# telemetry_receiver_wrap: IP-XACT component
VLNV tenstorrent.com:ocah:telemetry_receiver_wrap:1.0

## Address spaces and blocks
telemetry_receiver_wrap_mmap.telemetry_receiver_wrap: base 'h0, range 'h300, width 32

## Registers
Registers are 32-bit, read-only, reset 0x0 unless marked. A register's access mark holds for its fields unless they carry their own. Offsets are from the block's base; lines under a group give offsets from that group; [hi:lo] are bit positions; {n}, {i} and the like mark numbered series; 'fields as' and 'values as' point back to an identical list; <NAME> marks a mode.

## telemetry_receiver_wrap_mmap.telemetry_receiver_wrap — Wrapper address map instantiating the telemetry receiver channels.
Base 0x00000000
{0x0+0x100*i} telemetry_receiver[{i}] (i=0..2) group — Configuration, status, and data-buffer registers for a single telemetry receiver channel.
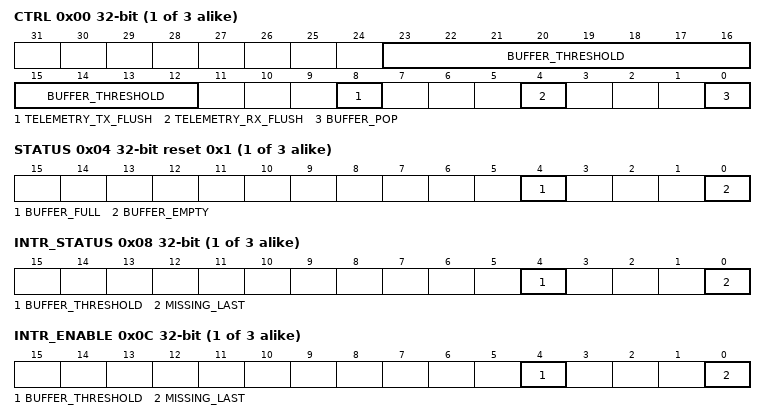
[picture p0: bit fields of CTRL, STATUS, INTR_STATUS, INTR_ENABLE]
  0x00 CTRL access per field — Control Register
    [23:12] BUFFER_THRESHOLD rw — Telemetry Message Buffer Threshold. The Telemetry Buffer Threshold Interrupt is asserted when the number of entries in the buffer is greater than this value. Only the low log2(queue depth)+1 bits are compared, so values alias modulo twice the queue depth, and only values below the queue depth can assert the interrupt.
    [8] TELEMETRY_TX_FLUSH rw — Telemetry Transmitter Flush. Writing `1` flushes all FIFOs in the telemetry transmitter. The flushing is done via the ATB AF interface. This bit clears itself when the transmitter acknowledges the flush. Writing `0` while a flush is pending withdraws the request, so other fields of this register must be updated with a read-modify-write while the bit is set.
    [4] TELEMETRY_RX_FLUSH wo — Telemetry Receiver Flush. Writing `1` discards queued messages and resets the assembly write pointer. Stored payload bytes are not cleared. In particular, a later short message can retain trailing counter values and validity from an earlier message. This operation does not erase storage.
    [0] BUFFER_POP wo — Telemetry Message Buffer Pop. Effective only if `STATUS.BUFFER_EMPTY = 0`. Writing `1` pops the buffer and thus updates the data in the `TELEMETRY_PROBE_ID`, `TELEMETRY_COUNTER_VLDS`, and `TELEMETRY_COUNTER[32]` registers.
  0x04 STATUS reset 0x1
    [4] BUFFER_FULL — Telemetry Message Buffer Full.
    [0] BUFFER_EMPTY — Telemetry Message Buffer Empty.
  0x08 INTR_STATUS access per field — Interrupt Status Register
    [4] BUFFER_THRESHOLD ro — Telemetry Message Buffer Threshold Interrupt. Asserted when the number of telemetry messages in the Telemetry Message Buffer is greater than `CTRL.BUFFER_THRESHOLD`.
    [0] MISSING_LAST rw write-1-clears — Last Packet Missing Interrupt. Asserted when the Telemetry Receiver has not received a Last Packet flag when the maximum number of packets a message can consist of has been received.
  0x0C INTR_ENABLE rw — Interrupt Enable Register
    [4] BUFFER_THRESHOLD — Telemetry Message Buffer Threshold Interrupt Enable.
    [0] MISSING_LAST — Last Packet Missing Interrupt Enable.
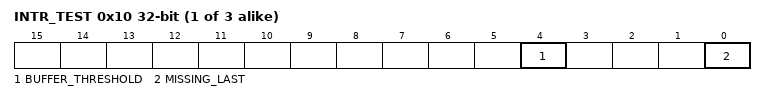
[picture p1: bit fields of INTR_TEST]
  0x10 INTR_TEST access per field — Interrupt Test Register
    [4] BUFFER_THRESHOLD rw — Telemetry Message Buffer Threshold Interrupt Test. Writing `1` forces the interrupt and writing `0` releases it.
    [0] MISSING_LAST wo — Last Packet Missing Interrupt Test. Writing `1` forces the interrupt.
  0x14 TELEMETRY_PROBE_ID
    [4:0] PROBE_ID — Probe ID. Contains the Probe ID field of the telemetry message at the bottom of the Telemetry Message Buffer.
  0x18 TELEMETRY_COUNTER_VLDS — Telemetry Counter Valid Bits Register
    [31:0] COUNTER_VLDS — Counter Valid Bits. Indicates which of the counter values in the telemetry message at the bottom of the Telemetry Message Buffer are valid. Bit `i` is for the `i`-th counter.
  {0x80+4j} TELEMETRY_COUNTER[{j}] (j=0..31)
    [31:0] COUNTER — Counter Value. Contains one of the 32 counter values in the telemetry message at the bottom of the Telemetry Message Buffer.

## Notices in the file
SPDX-License-Identifier: Apache-2.0
SPDX-FileCopyrightText: 2026 Tenstorrent USA, Inc.
